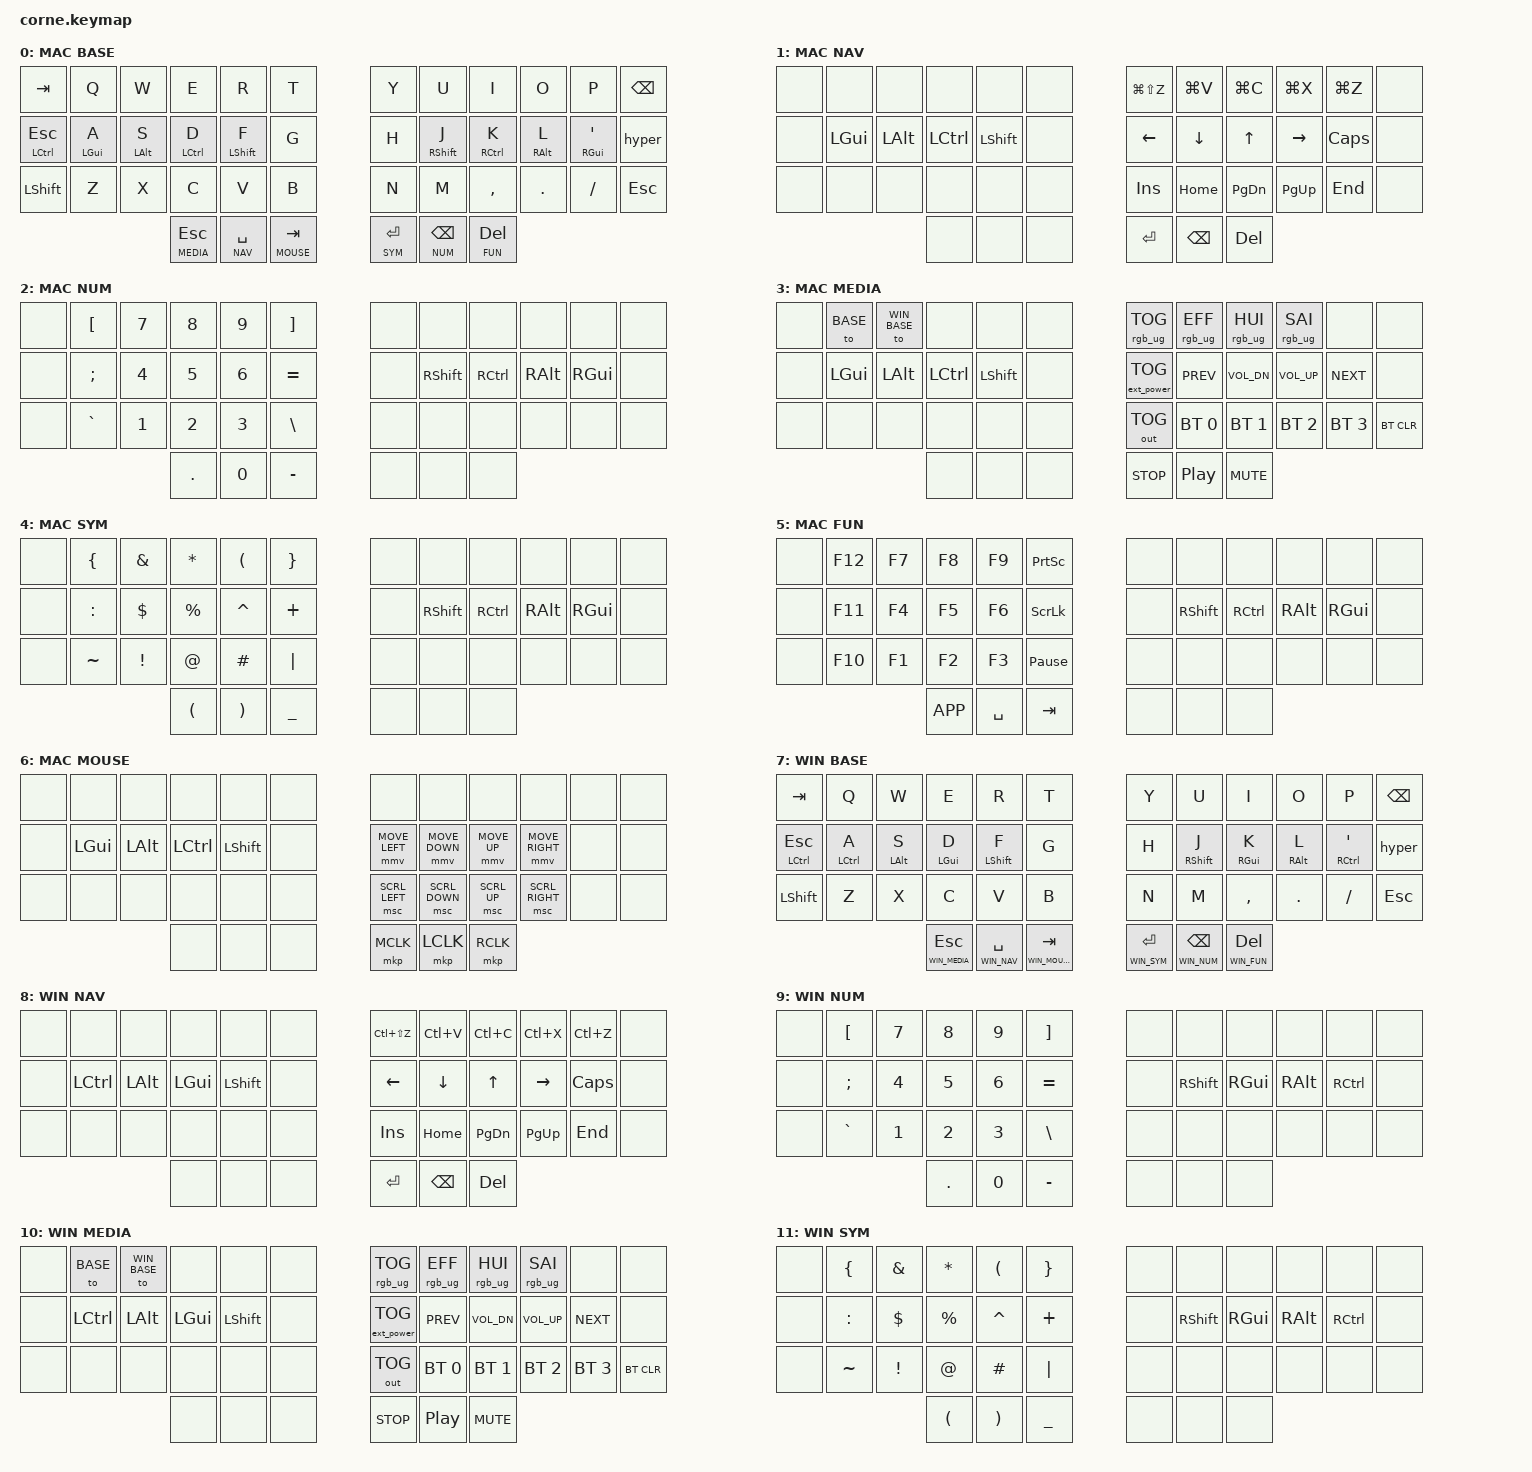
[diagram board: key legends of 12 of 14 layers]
/*
 * Copyright (c) 2020 The ZMK Contributors
 *
 * SPDX-License-Identifier: MIT
 */

//
//   Miryoku-style layout — QWERTY base, vim arrows (HJKL), GACS home row mods
//   Adapted from TOTEM config for Corne (42-key)
//
//   Layer 0: BASE    — QWERTY + home row mods
//   Layer 1: NAV     — vim arrows, clipboard, nav (hold SPACE)
//   Layer 2: NUM     — numpad left hand (hold BSPC)
//   Layer 3: MEDIA   — media, BT, RGB (hold ESC)
//   Layer 4: SYM     — symbols left hand (hold ENTER)
//   Layer 5: FUN     — function keys left hand (hold DEL)
//   Layer 6: MOUSE   — mouse movement, scroll, buttons (hold TAB)
//   Layers 7-13: Windows equivalents, in the same order.
//   Hold the ESC thumb, then tap Q for Mac or W for Windows.
//   Mode is independent of Bluetooth; reboot returns to Mac.

#include <behaviors.dtsi>
#include <dt-bindings/zmk/bt.h>
#include <dt-bindings/zmk/ext_power.h>
#include <dt-bindings/zmk/keys.h>
#include <dt-bindings/zmk/outputs.h>
#include <dt-bindings/zmk/pointing.h>
#include <dt-bindings/zmk/rgb.h>

#define BASE  0
#define NAV   1
#define NUM   2
#define MEDIA 3
#define SYM   4
#define FUN   5
#define MOUSE 6

// Windows uses a parallel layer bank so modifiers and combos follow the OS.
#define WIN_BASE 7
#define WIN_NAV 8
#define WIN_NUM 9
#define WIN_MEDIA 10
#define WIN_SYM 11
#define WIN_FUN 12
#define WIN_MOUSE 13

// Corne key positions (42 keys):
// Row 0:  0  1  2  3  4  5    6  7  8  9  10  11
// Row 1: 12 13 14 15 16 17   18 19 20 21  22  23
// Row 2: 24 25 26 27 28 29   30 31 32 33  34  35
// Thumb:          36 37 38   39 40 41

&mt {
    flavor = "tap-preferred";
    tapping-term-ms = <200>;
    quick-tap-ms = <175>;
    require-prior-idle-ms = <150>;
};

&lt {
    flavor = "balanced";
    tapping-term-ms = <200>;
    quick-tap-ms = <175>;
};

/ {
    combos {
        compatible = "zmk,combos";

        // -- Tier 1: Essential --

        combo_caps_word {
            bindings = <&caps_word>;
            key-positions = <16 19>;        // F + J (index home row)
            timeout-ms = <30>;
            require-prior-idle-ms = <150>;
        };

        combo_esc {
            bindings = <&kp ESC>;
            key-positions = <2 3>;          // W + E
            timeout-ms = <30>;
            require-prior-idle-ms = <150>;
        };

        combo_bspc {
            bindings = <&kp BSPC>;
            key-positions = <8 9>;          // I + O
            timeout-ms = <30>;
            require-prior-idle-ms = <150>;
        };

        combo_del {
            bindings = <&kp DEL>;
            key-positions = <9 10>;         // O + P
            timeout-ms = <30>;
            require-prior-idle-ms = <150>;
        };

        // -- Tier 2: High Value --

        combo_tab {
            bindings = <&kp TAB>;
            key-positions = <14 15>;        // S + D
            timeout-ms = <30>;
            require-prior-idle-ms = <150>;
        };

        combo_enter {
            bindings = <&kp RET>;
            key-positions = <20 21>;        // K + L
            timeout-ms = <30>;
            require-prior-idle-ms = <150>;
        };

        combo_copy {
            layers = <BASE NAV NUM MEDIA SYM FUN MOUSE>;
            bindings = <&kp LG(C)>;
            key-positions = <26 27>;        // X + C
            timeout-ms = <30>;
            require-prior-idle-ms = <150>;
        };

        combo_paste {
            layers = <BASE NAV NUM MEDIA SYM FUN MOUSE>;
            bindings = <&kp LG(V)>;
            key-positions = <27 28>;        // C + V
            timeout-ms = <30>;
            require-prior-idle-ms = <150>;
        };

        combo_cut {
            layers = <BASE NAV NUM MEDIA SYM FUN MOUSE>;
            bindings = <&kp LG(X)>;
            key-positions = <26 28>;        // X + V (skip middle)
            timeout-ms = <30>;
            require-prior-idle-ms = <150>;
        };

        combo_win_copy {
            layers = <WIN_BASE WIN_NAV WIN_NUM WIN_MEDIA WIN_SYM WIN_FUN WIN_MOUSE>;
            bindings = <&kp LC(C)>;
            key-positions = <26 27>;        // X + C
            timeout-ms = <30>;
            require-prior-idle-ms = <150>;
        };

        combo_win_paste {
            layers = <WIN_BASE WIN_NAV WIN_NUM WIN_MEDIA WIN_SYM WIN_FUN WIN_MOUSE>;
            bindings = <&kp LC(V)>;
            key-positions = <27 28>;        // C + V
            timeout-ms = <30>;
            require-prior-idle-ms = <150>;
        };

        combo_win_cut {
            layers = <WIN_BASE WIN_NAV WIN_NUM WIN_MEDIA WIN_SYM WIN_FUN WIN_MOUSE>;
            bindings = <&kp LC(X)>;
            key-positions = <26 28>;        // X + V (skip middle)
            timeout-ms = <30>;
            require-prior-idle-ms = <150>;
        };

        // -- Tier 3: Vertical Symbol Combos --

        combo_minus {
            bindings = <&kp MINUS>;
            key-positions = <19 31>;        // J + M (right index vertical)
            timeout-ms = <40>;
            require-prior-idle-ms = <100>;
        };

        combo_underscore {
            bindings = <&kp UNDER>;
            key-positions = <18 30>;        // H + N (right inner vertical)
            timeout-ms = <40>;
            require-prior-idle-ms = <100>;
        };

        combo_equal {
            bindings = <&kp EQUAL>;
            key-positions = <16 28>;        // F + V (left index vertical)
            timeout-ms = <40>;
            require-prior-idle-ms = <100>;
        };

        combo_grave {
            bindings = <&kp GRAVE>;
            key-positions = <14 26>;        // S + X (left ring vertical)
            timeout-ms = <40>;
            require-prior-idle-ms = <100>;
        };

        combo_semi {
            bindings = <&kp SEMI>;
            key-positions = <21 22>;        // L + ' (right ring+pinky home)
            timeout-ms = <30>;
            require-prior-idle-ms = <150>;
        };
    };

    macros {
        hyper: hyper {
            compatible = "zmk,behavior-macro";
            #binding-cells = <0>;
            bindings =
                <&macro_press &kp LGUI &kp LALT &kp LCTRL &kp LSHFT>,
                <&macro_pause_for_release>,
                <&macro_release &kp LGUI &kp LALT &kp LCTRL &kp LSHFT>;
        };
    };

    keymap {
        compatible = "zmk,keymap";

        base_layer {
            display-name = "MAC BASE";
            bindings = <
&kp TAB        &kp Q       &kp W       &kp E         &kp R         &kp T          &kp Y       &kp U         &kp I         &kp O        &kp P        &kp BSPC
&mt LCTRL ESC  &mt LGUI A  &mt LALT S  &mt LCTRL D   &mt LSHFT F   &kp G          &kp H       &mt RSHFT J   &mt RCTRL K   &mt RALT L   &mt RGUI SQT &hyper
&kp LSHFT      &kp Z       &kp X       &kp C         &kp V         &kp B          &kp N       &kp M         &kp COMMA     &kp DOT      &kp FSLH     &kp ESC
                                        &lt MEDIA ESC &lt NAV SPACE &lt MOUSE TAB  &lt SYM RET &lt NUM BSPC  &lt FUN DEL
            >;
        };

        nav_layer {
            display-name = "MAC NAV";
            bindings = <
&none          &none       &none       &none         &none         &none          &kp LG(LS(Z)) &kp LG(V)   &kp LG(C)     &kp LG(X)    &kp LG(Z)    &none
&none          &kp LGUI    &kp LALT    &kp LCTRL     &kp LSHFT     &none          &kp LEFT    &kp DOWN      &kp UP        &kp RIGHT    &kp CAPS     &none
&none          &none       &none       &none         &none         &none          &kp INS     &kp HOME      &kp PG_DN     &kp PG_UP    &kp END      &none
                                       &none         &none         &none          &kp RET     &kp BSPC      &kp DEL
            >;
        };

        num_layer {
            display-name = "MAC NUM";
            bindings = <
&none          &kp LBKT    &kp N7      &kp N8        &kp N9        &kp RBKT       &none       &none         &none         &none        &none        &none
&none          &kp SEMI    &kp N4      &kp N5        &kp N6        &kp EQUAL      &none       &kp RSHFT     &kp RCTRL     &kp RALT     &kp RGUI     &none
&none          &kp GRAVE   &kp N1      &kp N2        &kp N3        &kp BSLH       &none       &none         &none         &none        &none        &none
                                       &kp DOT       &kp N0        &kp MINUS      &none       &none         &none
            >;
        };

        media_layer {
            display-name = "MAC MEDIA";
            bindings = <
&none          &to BASE  &to WIN_BASE       &none         &none         &none          &rgb_ug RGB_TOG &rgb_ug RGB_EFF &rgb_ug RGB_HUI &rgb_ug RGB_SAI &none      &none
&none          &kp LGUI    &kp LALT    &kp LCTRL     &kp LSHFT     &none          &ext_power EP_TOG &kp C_PREV  &kp C_VOL_DN  &kp C_VOL_UP &kp C_NEXT   &none
&none          &none       &none       &none         &none         &none          &out OUT_TOG &bt BT_SEL 0  &bt BT_SEL 1  &bt BT_SEL 2 &bt BT_SEL 3 &bt BT_CLR
                                       &none         &none         &none          &kp C_STOP  &kp C_PP      &kp C_MUTE
            >;
        };

        sym_layer {
            display-name = "MAC SYM";
            bindings = <
&none          &kp LBRC    &kp AMPS    &kp ASTRK     &kp LPAR      &kp RBRC       &none       &none         &none         &none        &none        &none
&none          &kp COLON   &kp DLLR    &kp PRCNT     &kp CARET     &kp PLUS       &none       &kp RSHFT     &kp RCTRL     &kp RALT     &kp RGUI     &none
&none          &kp TILDE   &kp EXCL    &kp AT        &kp HASH      &kp PIPE       &none       &none         &none         &none        &none        &none
                                       &kp LPAR      &kp RPAR      &kp UNDER      &none       &none         &none
            >;
        };

        fun_layer {
            display-name = "MAC FUN";
            bindings = <
&none          &kp F12     &kp F7      &kp F8        &kp F9        &kp PSCRN      &none       &none         &none         &none        &none        &none
&none          &kp F11     &kp F4      &kp F5        &kp F6        &kp SLCK       &none       &kp RSHFT     &kp RCTRL     &kp RALT     &kp RGUI     &none
&none          &kp F10     &kp F1      &kp F2        &kp F3        &kp PAUSE_BREAK &none      &none         &none         &none        &none        &none
                                       &kp K_APP     &kp SPACE     &kp TAB        &none       &none         &none
            >;
        };

        mouse_layer {
            display-name = "MAC MOUSE";
            bindings = <
&none          &none       &none       &none         &none         &none          &none            &none            &none          &none             &none        &none
&none          &kp LGUI    &kp LALT    &kp LCTRL     &kp LSHFT     &none          &mmv MOVE_LEFT   &mmv MOVE_DOWN   &mmv MOVE_UP   &mmv MOVE_RIGHT   &none        &none
&none          &none       &none       &none         &none         &none          &msc SCRL_LEFT   &msc SCRL_DOWN   &msc SCRL_UP   &msc SCRL_RIGHT   &none        &none
                                       &none         &none         &none          &mkp MCLK        &mkp LCLK        &mkp RCLK
            >;
        };

        win_base_layer {
            display-name = "WIN BASE";
            bindings = <
&kp TAB        &kp Q       &kp W       &kp E         &kp R         &kp T          &kp Y       &kp U         &kp I         &kp O        &kp P        &kp BSPC
&mt LCTRL ESC  &mt LCTRL A  &mt LALT S  &mt LGUI D   &mt LSHFT F   &kp G          &kp H       &mt RSHFT J   &mt RGUI K   &mt RALT L   &mt RCTRL SQT &hyper
&kp LSHFT      &kp Z       &kp X       &kp C         &kp V         &kp B          &kp N       &kp M         &kp COMMA     &kp DOT      &kp FSLH     &kp ESC
                                        &lt WIN_MEDIA ESC &lt WIN_NAV SPACE &lt WIN_MOUSE TAB  &lt WIN_SYM RET &lt WIN_NUM BSPC  &lt WIN_FUN DEL
            >;
        };

        win_nav_layer {
            display-name = "WIN NAV";
            bindings = <
&none          &none       &none       &none         &none         &none          &kp LC(LS(Z)) &kp LC(V)   &kp LC(C)     &kp LC(X)    &kp LC(Z)    &none
&none          &kp LCTRL    &kp LALT    &kp LGUI     &kp LSHFT     &none          &kp LEFT    &kp DOWN      &kp UP        &kp RIGHT    &kp CAPS     &none
&none          &none       &none       &none         &none         &none          &kp INS     &kp HOME      &kp PG_DN     &kp PG_UP    &kp END      &none
                                       &none         &none         &none          &kp RET     &kp BSPC      &kp DEL
            >;
        };

        win_num_layer {
            display-name = "WIN NUM";
            bindings = <
&none          &kp LBKT    &kp N7      &kp N8        &kp N9        &kp RBKT       &none       &none         &none         &none        &none        &none
&none          &kp SEMI    &kp N4      &kp N5        &kp N6        &kp EQUAL      &none       &kp RSHFT     &kp RGUI     &kp RALT     &kp RCTRL     &none
&none          &kp GRAVE   &kp N1      &kp N2        &kp N3        &kp BSLH       &none       &none         &none         &none        &none        &none
                                       &kp DOT       &kp N0        &kp MINUS      &none       &none         &none
            >;
        };

        win_media_layer {
            display-name = "WIN MEDIA";
            bindings = <
&none          &to BASE  &to WIN_BASE       &none         &none         &none          &rgb_ug RGB_TOG &rgb_ug RGB_EFF &rgb_ug RGB_HUI &rgb_ug RGB_SAI &none      &none
&none          &kp LCTRL    &kp LALT    &kp LGUI     &kp LSHFT     &none          &ext_power EP_TOG &kp C_PREV  &kp C_VOL_DN  &kp C_VOL_UP &kp C_NEXT   &none
&none          &none       &none       &none         &none         &none          &out OUT_TOG &bt BT_SEL 0  &bt BT_SEL 1  &bt BT_SEL 2 &bt BT_SEL 3 &bt BT_CLR
                                       &none         &none         &none          &kp C_STOP  &kp C_PP      &kp C_MUTE
            >;
        };

        win_sym_layer {
            display-name = "WIN SYM";
            bindings = <
&none          &kp LBRC    &kp AMPS    &kp ASTRK     &kp LPAR      &kp RBRC       &none       &none         &none         &none        &none        &none
&none          &kp COLON   &kp DLLR    &kp PRCNT     &kp CARET     &kp PLUS       &none       &kp RSHFT     &kp RGUI     &kp RALT     &kp RCTRL     &none
&none          &kp TILDE   &kp EXCL    &kp AT        &kp HASH      &kp PIPE       &none       &none         &none         &none        &none        &none
                                       &kp LPAR      &kp RPAR      &kp UNDER      &none       &none         &none
            >;
        };

        win_fun_layer {
            display-name = "WIN FUN";
            bindings = <
&none          &kp F12     &kp F7      &kp F8        &kp F9        &kp PSCRN      &none       &none         &none         &none        &none        &none
&none          &kp F11     &kp F4      &kp F5        &kp F6        &kp SLCK       &none       &kp RSHFT     &kp RGUI     &kp RALT     &kp RCTRL     &none
&none          &kp F10     &kp F1      &kp F2        &kp F3        &kp PAUSE_BREAK &none      &none         &none         &none        &none        &none
                                       &kp K_APP     &kp SPACE     &kp TAB        &none       &none         &none
            >;
        };

        win_mouse_layer {
            display-name = "WIN MOUSE";
            bindings = <
&none          &none       &none       &none         &none         &none          &none            &none            &none          &none             &none        &none
&none          &kp LCTRL    &kp LALT    &kp LGUI     &kp LSHFT     &none          &mmv MOVE_LEFT   &mmv MOVE_DOWN   &mmv MOVE_UP   &mmv MOVE_RIGHT   &none        &none
&none          &none       &none       &none         &none         &none          &msc SCRL_LEFT   &msc SCRL_DOWN   &msc SCRL_UP   &msc SCRL_RIGHT   &none        &none
                                       &none         &none         &none          &mkp MCLK        &mkp LCLK        &mkp RCLK
            >;
        };
    };
};
